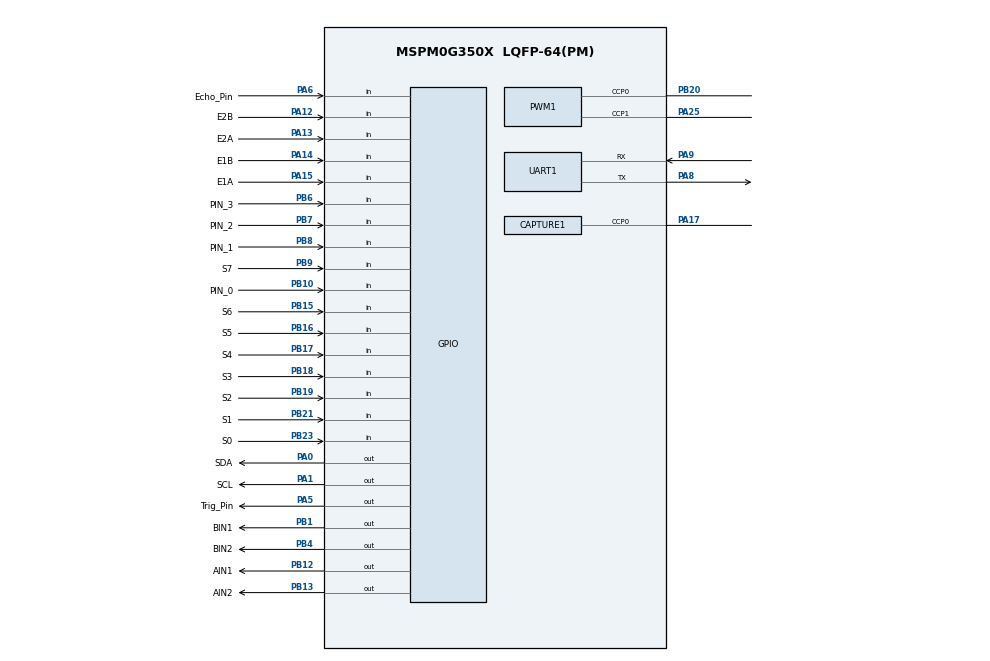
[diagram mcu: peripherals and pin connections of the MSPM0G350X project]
/**
 * @cliArgs --device "MSPM0G350X" --package "LQFP-64(PM)" --part "Default" --product "mspm0_sdk@2.01.00.03"
 * @versions {"tool":"1.20.0+3587"}
 */

/**
 * Import the modules used in this configuration.
 */
const CAPTURE  = scripting.addModule("/ti/driverlib/CAPTURE", {}, false);
const CAPTURE1 = CAPTURE.addInstance();
const GPIO     = scripting.addModule("/ti/driverlib/GPIO", {}, false);
const GPIO1    = GPIO.addInstance();
const GPIO2    = GPIO.addInstance();
const GPIO3    = GPIO.addInstance();
const GPIO4    = GPIO.addInstance();
const GPIO5    = GPIO.addInstance();
const GPIO6    = GPIO.addInstance();
const GPIO7    = GPIO.addInstance();
const GPIO8    = GPIO.addInstance();
const PWM      = scripting.addModule("/ti/driverlib/PWM", {}, false);
const PWM1     = PWM.addInstance();
const SYSCTL   = scripting.addModule("/ti/driverlib/SYSCTL");
const TIMER    = scripting.addModule("/ti/driverlib/TIMER", {}, false);
const TIMER1   = TIMER.addInstance();
const TIMER2   = TIMER.addInstance();
const UART     = scripting.addModule("/ti/driverlib/UART", {}, false);
const UART1    = UART.addInstance();

/**
 * Write custom configuration values to the imported modules.
 */
const divider6       = system.clockTree["PLL_CLK2X_DIV"];
divider6.divideValue = 4;

const divider7       = system.clockTree["PLL_PDIV"];
divider7.divideValue = 2;

const divider9       = system.clockTree["UDIV"];
divider9.divideValue = 2;

const multiplier2         = system.clockTree["PLL_QDIV"];
multiplier2.multiplyValue = 10;

const mux8       = system.clockTree["HSCLKMUX"];
mux8.inputSelect = "HSCLKMUX_SYSPLL2X";

const pinFunction4       = system.clockTree["HFXT"];
pinFunction4.HFXTStartup = 10;

CAPTURE1.$name                      = "CAPTURE_0";
CAPTURE1.timerPeriod                = "10 ms";
CAPTURE1.timerClkPrescale           = 256;
CAPTURE1.timerClkDiv                = 8;
CAPTURE1.peripheral.$assign         = "TIMA1";
CAPTURE1.peripheral.ccp0Pin.$assign = "PA17";
CAPTURE1.ccp0PinConfig.$name        = "ti_driverlib_gpio_GPIOPinGeneric2";

const Board = scripting.addModule("/ti/driverlib/Board", {}, false);

GPIO1.$name                              = "LEDB";
GPIO1.port                               = "PORTB";
GPIO1.associatedPins[0].internalResistor = "PULL_DOWN";
GPIO1.associatedPins[0].assignedPin      = "22";
GPIO1.associatedPins[0].$name            = "PIN_22";

GPIO2.$name                         = "TRACK_SENSOR";
GPIO2.port                          = "PORTB";
GPIO2.associatedPins.create(8);
GPIO2.associatedPins[0].direction   = "INPUT";
GPIO2.associatedPins[0].ioStructure = "SD";
GPIO2.associatedPins[0].$name       = "S0";
GPIO2.associatedPins[0].pin.$assign = "PB23";
GPIO2.associatedPins[1].$name       = "S1";
GPIO2.associatedPins[1].direction   = "INPUT";
GPIO2.associatedPins[1].ioStructure = "SD";
GPIO2.associatedPins[1].pin.$assign = "PB21";
GPIO2.associatedPins[2].$name       = "S2";
GPIO2.associatedPins[2].direction   = "INPUT";
GPIO2.associatedPins[2].ioStructure = "SD";
GPIO2.associatedPins[2].pin.$assign = "PB19";
GPIO2.associatedPins[3].$name       = "S3";
GPIO2.associatedPins[3].direction   = "INPUT";
GPIO2.associatedPins[3].ioStructure = "SD";
GPIO2.associatedPins[3].pin.$assign = "PB18";
GPIO2.associatedPins[4].$name       = "S4";
GPIO2.associatedPins[4].direction   = "INPUT";
GPIO2.associatedPins[4].ioStructure = "SD";
GPIO2.associatedPins[4].pin.$assign = "PB17";
GPIO2.associatedPins[5].$name       = "S5";
GPIO2.associatedPins[5].direction   = "INPUT";
GPIO2.associatedPins[5].ioStructure = "SD";
GPIO2.associatedPins[5].pin.$assign = "PB16";
GPIO2.associatedPins[6].$name       = "S6";
GPIO2.associatedPins[6].direction   = "INPUT";
GPIO2.associatedPins[6].ioStructure = "SD";
GPIO2.associatedPins[6].pin.$assign = "PB15";
GPIO2.associatedPins[7].$name       = "S7";
GPIO2.associatedPins[7].direction   = "INPUT";
GPIO2.associatedPins[7].ioStructure = "SD";
GPIO2.associatedPins[7].pin.$assign = "PB9";

GPIO3.$name                         = "MOTOR";
GPIO3.port                          = "PORTB";
GPIO3.associatedPins.create(4);
GPIO3.associatedPins[0].$name       = "AIN1";
GPIO3.associatedPins[0].pin.$assign = "PB12";
GPIO3.associatedPins[1].$name       = "AIN2";
GPIO3.associatedPins[1].pin.$assign = "PB13";
GPIO3.associatedPins[2].$name       = "BIN1";
GPIO3.associatedPins[2].pin.$assign = "PB1";
GPIO3.associatedPins[3].$name       = "BIN2";
GPIO3.associatedPins[3].pin.$assign = "PB4";

GPIO4.$name                              = "ENCODERA";
GPIO4.port                               = "PORTA";
GPIO4.associatedPins.create(2);
GPIO4.associatedPins[0].$name            = "E1A";
GPIO4.associatedPins[0].direction        = "INPUT";
GPIO4.associatedPins[0].interruptEn      = true;
GPIO4.associatedPins[0].polarity         = "RISE";
GPIO4.associatedPins[0].internalResistor = "PULL_UP";
GPIO4.associatedPins[0].pin.$assign      = "PA15";
GPIO4.associatedPins[1].$name            = "E1B";
GPIO4.associatedPins[1].direction        = "INPUT";
GPIO4.associatedPins[1].internalResistor = "PULL_UP";
GPIO4.associatedPins[1].interruptEn      = true;
GPIO4.associatedPins[1].polarity         = "RISE";
GPIO4.associatedPins[1].pin.$assign      = "PA14";

GPIO5.$name                               = "ENCODERB";
GPIO5.port                                = "PORTA";
GPIO5.associatedPins.create(2);
GPIO5.associatedPins[0].$name             = "E2A";
GPIO5.associatedPins[0].direction         = "INPUT";
GPIO5.associatedPins[0].internalResistor  = "PULL_UP";
GPIO5.associatedPins[0].interruptEn       = true;
GPIO5.associatedPins[0].polarity          = "RISE";
GPIO5.associatedPins[0].interruptPriority = "0";
GPIO5.associatedPins[0].pin.$assign       = "PA13";
GPIO5.associatedPins[1].$name             = "E2B";
GPIO5.associatedPins[1].direction         = "INPUT";
GPIO5.associatedPins[1].internalResistor  = "PULL_UP";
GPIO5.associatedPins[1].interruptEn       = true;
GPIO5.associatedPins[1].polarity          = "RISE";
GPIO5.associatedPins[1].interruptPriority = "0";
GPIO5.associatedPins[1].pin.$assign       = "PA12";

GPIO6.$name                         = "OLED_Pin";
GPIO6.port                          = "PORTA";
GPIO6.associatedPins.create(2);
GPIO6.associatedPins[0].$name       = "SDA";
GPIO6.associatedPins[0].pin.$assign = "PA0";
GPIO6.associatedPins[1].$name       = "SCL";
GPIO6.associatedPins[1].pin.$assign = "PA1";

GPIO7.$name                         = "Key_Pins";
GPIO7.port                          = "PORTB";
GPIO7.associatedPins.create(4);
GPIO7.associatedPins[0].$name       = "PIN_0";
GPIO7.associatedPins[0].direction   = "INPUT";
GPIO7.associatedPins[0].pin.$assign = "PB10";
GPIO7.associatedPins[1].$name       = "PIN_1";
GPIO7.associatedPins[1].direction   = "INPUT";
GPIO7.associatedPins[1].pin.$assign = "PB8";
GPIO7.associatedPins[2].$name       = "PIN_2";
GPIO7.associatedPins[2].direction   = "INPUT";
GPIO7.associatedPins[2].pin.$assign = "PB7";
GPIO7.associatedPins[3].$name       = "PIN_3";
GPIO7.associatedPins[3].direction   = "INPUT";
GPIO7.associatedPins[3].pin.$assign = "PB6";

GPIO8.$name                         = "Ultrasonic_Pins";
GPIO8.port                          = "PORTA";
GPIO8.associatedPins.create(2);
GPIO8.associatedPins[0].$name       = "Trig_Pin";
GPIO8.associatedPins[0].pin.$assign = "PA5";
GPIO8.associatedPins[1].$name       = "Echo_Pin";
GPIO8.associatedPins[1].direction   = "INPUT";
GPIO8.associatedPins[1].pin.$assign = "PA6";

PWM1.$name                      = "PWM_0";
PWM1.timerStartTimer            = true;
PWM1.pwmMode                    = "EDGE_ALIGN_UP";
PWM1.peripheral.$assign         = "TIMG12";
PWM1.peripheral.ccp0Pin.$assign = "PB20";
PWM1.peripheral.ccp1Pin.$assign = "PA25";
PWM1.PWM_CHANNEL_0.$name        = "ti_driverlib_pwm_PWMTimerCC0";
PWM1.PWM_CHANNEL_1.$name        = "ti_driverlib_pwm_PWMTimerCC1";
PWM1.ccp0PinConfig.$name        = "ti_driverlib_gpio_GPIOPinGeneric0";
PWM1.ccp0PinConfig.enableConfig = true;
PWM1.ccp1PinConfig.$name        = "ti_driverlib_gpio_GPIOPinGeneric1";
PWM1.ccp1PinConfig.enableConfig = true;

SYSCTL.forceDefaultClkConfig = true;

TIMER1.$name              = "TIMER_0";
TIMER1.timerClkDiv        = 8;
TIMER1.timerClkPrescale   = 200;
TIMER1.timerPeriod        = "10 ms";
TIMER1.timerMode          = "PERIODIC";
TIMER1.timerStartTimer    = true;
TIMER1.interrupts         = ["ZERO"];
TIMER1.interruptPriority  = "1";
TIMER1.peripheral.$assign = "TIMA0";

TIMER2.$name              = "TIMER_US";
TIMER2.timerPeriod = "65 ms";
TIMER2.timerClkPrescale   = 32;
TIMER2.timerMode          = "PERIODIC_UP";
TIMER2.interrupts = [];
TIMER2.peripheral.$assign = "TIMG6";

UART1.$name                    = "UART_0";
UART1.peripheral.rxPin.$assign = "PA9";
UART1.peripheral.txPin.$assign = "PA8";
UART1.txPinConfig.$name        = "ti_driverlib_gpio_GPIOPinGeneric3";
UART1.rxPinConfig.$name        = "ti_driverlib_gpio_GPIOPinGeneric4";

/**
 * Pinmux solution for unlocked pins/peripherals. This ensures that minor changes to the automatic solver in a future
 * version of the tool will not impact the pinmux you originally saw.  These lines can be completely deleted in order to
 * re-solve from scratch.
 */
Board.peripheral.$suggestSolution            = "DEBUGSS";
Board.peripheral.swclkPin.$suggestSolution   = "PA20";
Board.peripheral.swdioPin.$suggestSolution   = "PA19";
GPIO1.associatedPins[0].pin.$suggestSolution = "PB22";
SYSCTL.peripheral.$suggestSolution           = "SYSCTL";
UART1.peripheral.$suggestSolution            = "UART1";
